# comp register map
Vendor: Texas Instruments
Peripheral module from a debugger description file (folder sc4cc231e6pm).
Registers are 32-bit, read-write, no defined reset value unless marked. A register's access mark holds for its fields unless they carry their own. Offsets are as the file gives them; lines under a group give offsets from that group; [hi:lo] are bit positions; {n}, {i} and the like mark numbered series; 'fields as' and 'values as' point back to an identical list; <NAME> marks a mode.

## COMP — Comparator register offsets
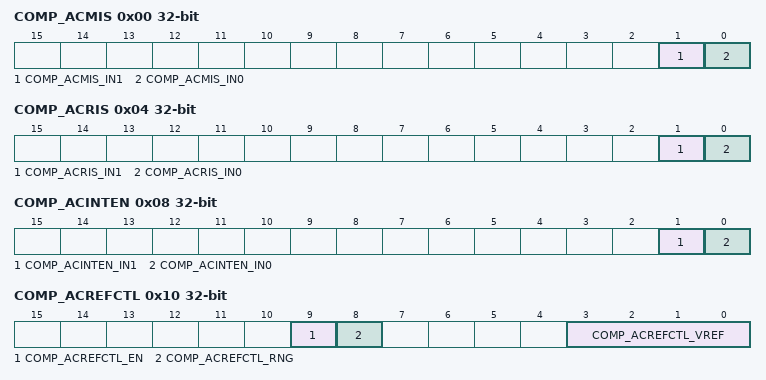
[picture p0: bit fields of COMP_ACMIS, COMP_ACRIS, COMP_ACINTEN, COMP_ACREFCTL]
0x00 COMP_ACMIS — Analog Comparator Masked Interrupt Status
  [1] COMP_ACMIS_IN1 — Comparator 1 Masked Interrupt Status
  [0] COMP_ACMIS_IN0 — Comparator 0 Masked Interrupt Status
0x04 COMP_ACRIS ro — Analog Comparator Raw Interrupt Status
  [1] COMP_ACRIS_IN1 — Comparator 1 Interrupt Status
  [0] COMP_ACRIS_IN0 — Comparator 0 Interrupt Status
0x08 COMP_ACINTEN — Analog Comparator Interrupt Enable
  [1] COMP_ACINTEN_IN1 — Comparator 1 Interrupt Enable
  [0] COMP_ACINTEN_IN0 — Comparator 0 Interrupt Enable
0x10 COMP_ACREFCTL — Analog Comparator Reference Voltage Control
  [9] COMP_ACREFCTL_EN — Resistor Ladder Enable
  [8] COMP_ACREFCTL_RNG — Resistor Ladder Range
  [3:0] COMP_ACREFCTL_VREF — Resistor Ladder Voltage Ref
0x20 COMP_ACSTAT0 ro — Analog Comparator Status 0
  [1] COMP_ACSTAT0_OVAL — Comparator Output Value
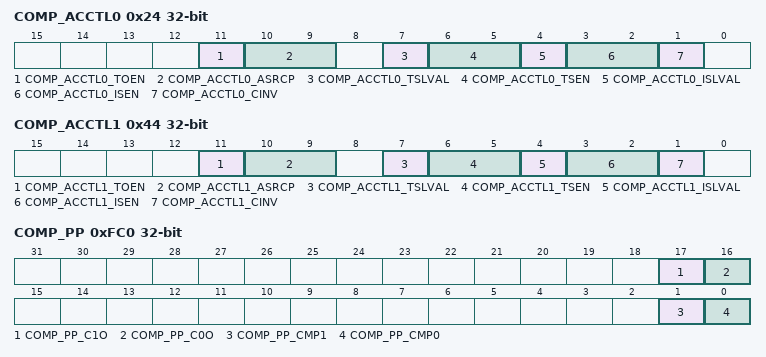
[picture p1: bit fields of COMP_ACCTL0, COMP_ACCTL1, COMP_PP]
0x24 COMP_ACCTL0 — Analog Comparator Control 0
  [11] COMP_ACCTL0_TOEN — Trigger Output Enable
  [10:9] COMP_ACCTL0_ASRCP — Analog Source Positive
    0=COMP_ACCTL0_ASRCP_PIN (Pin value of Cn+); 1=COMP_ACCTL0_ASRCP_PIN0 (Pin value of C0+); 2=COMP_ACCTL0_ASRCP_REF (Internal voltage reference)
  [7] COMP_ACCTL0_TSLVAL — Trigger Sense Level Value
  [6:5] COMP_ACCTL0_TSEN — Trigger Sense
    0=COMP_ACCTL0_TSEN_LEVEL (Level sense, see TSLVAL); 1=COMP_ACCTL0_TSEN_FALL (Falling edge); 2=COMP_ACCTL0_TSEN_RISE (Rising edge); 3=COMP_ACCTL0_TSEN_BOTH (Either edge)
  [4] COMP_ACCTL0_ISLVAL — Interrupt Sense Level Value
  [3:2] COMP_ACCTL0_ISEN — Interrupt Sense
    0=COMP_ACCTL0_ISEN_LEVEL (Level sense, see ISLVAL); 1=COMP_ACCTL0_ISEN_FALL (Falling edge); 2=COMP_ACCTL0_ISEN_RISE (Rising edge); 3=COMP_ACCTL0_ISEN_BOTH (Either edge)
  [1] COMP_ACCTL0_CINV — Comparator Output Invert
0x40 COMP_ACSTAT1 ro — Analog Comparator Status 1
  [1] COMP_ACSTAT1_OVAL — Comparator Output Value
0x44 COMP_ACCTL1 — Analog Comparator Control 1
  [11] COMP_ACCTL1_TOEN — Trigger Output Enable
  [10:9] COMP_ACCTL1_ASRCP — Analog Source Positive
    0=COMP_ACCTL1_ASRCP_PIN (Pin value of Cn+); 1=COMP_ACCTL1_ASRCP_PIN0 (Pin value of C0+); 2=COMP_ACCTL1_ASRCP_REF (Internal voltage reference)
  [7] COMP_ACCTL1_TSLVAL — Trigger Sense Level Value
  [6:5] COMP_ACCTL1_TSEN — Trigger Sense
    0=COMP_ACCTL1_TSEN_LEVEL (Level sense, see TSLVAL); 1=COMP_ACCTL1_TSEN_FALL (Falling edge); 2=COMP_ACCTL1_TSEN_RISE (Rising edge); 3=COMP_ACCTL1_TSEN_BOTH (Either edge)
  [4] COMP_ACCTL1_ISLVAL — Interrupt Sense Level Value
  [3:2] COMP_ACCTL1_ISEN — Interrupt Sense
    0=COMP_ACCTL1_ISEN_LEVEL (Level sense, see ISLVAL); 1=COMP_ACCTL1_ISEN_FALL (Falling edge); 2=COMP_ACCTL1_ISEN_RISE (Rising edge); 3=COMP_ACCTL1_ISEN_BOTH (Either edge)
  [1] COMP_ACCTL1_CINV — Comparator Output Invert
0xFC0 COMP_PP ro — Analog Comparator Peripheral Properties
  [17] COMP_PP_C1O — Comparator Output 1 Present
  [16] COMP_PP_C0O — Comparator Output 0 Present
  [1] COMP_PP_CMP1 — Comparator 1 Present
  [0] COMP_PP_CMP0 — Comparator 0 Present
